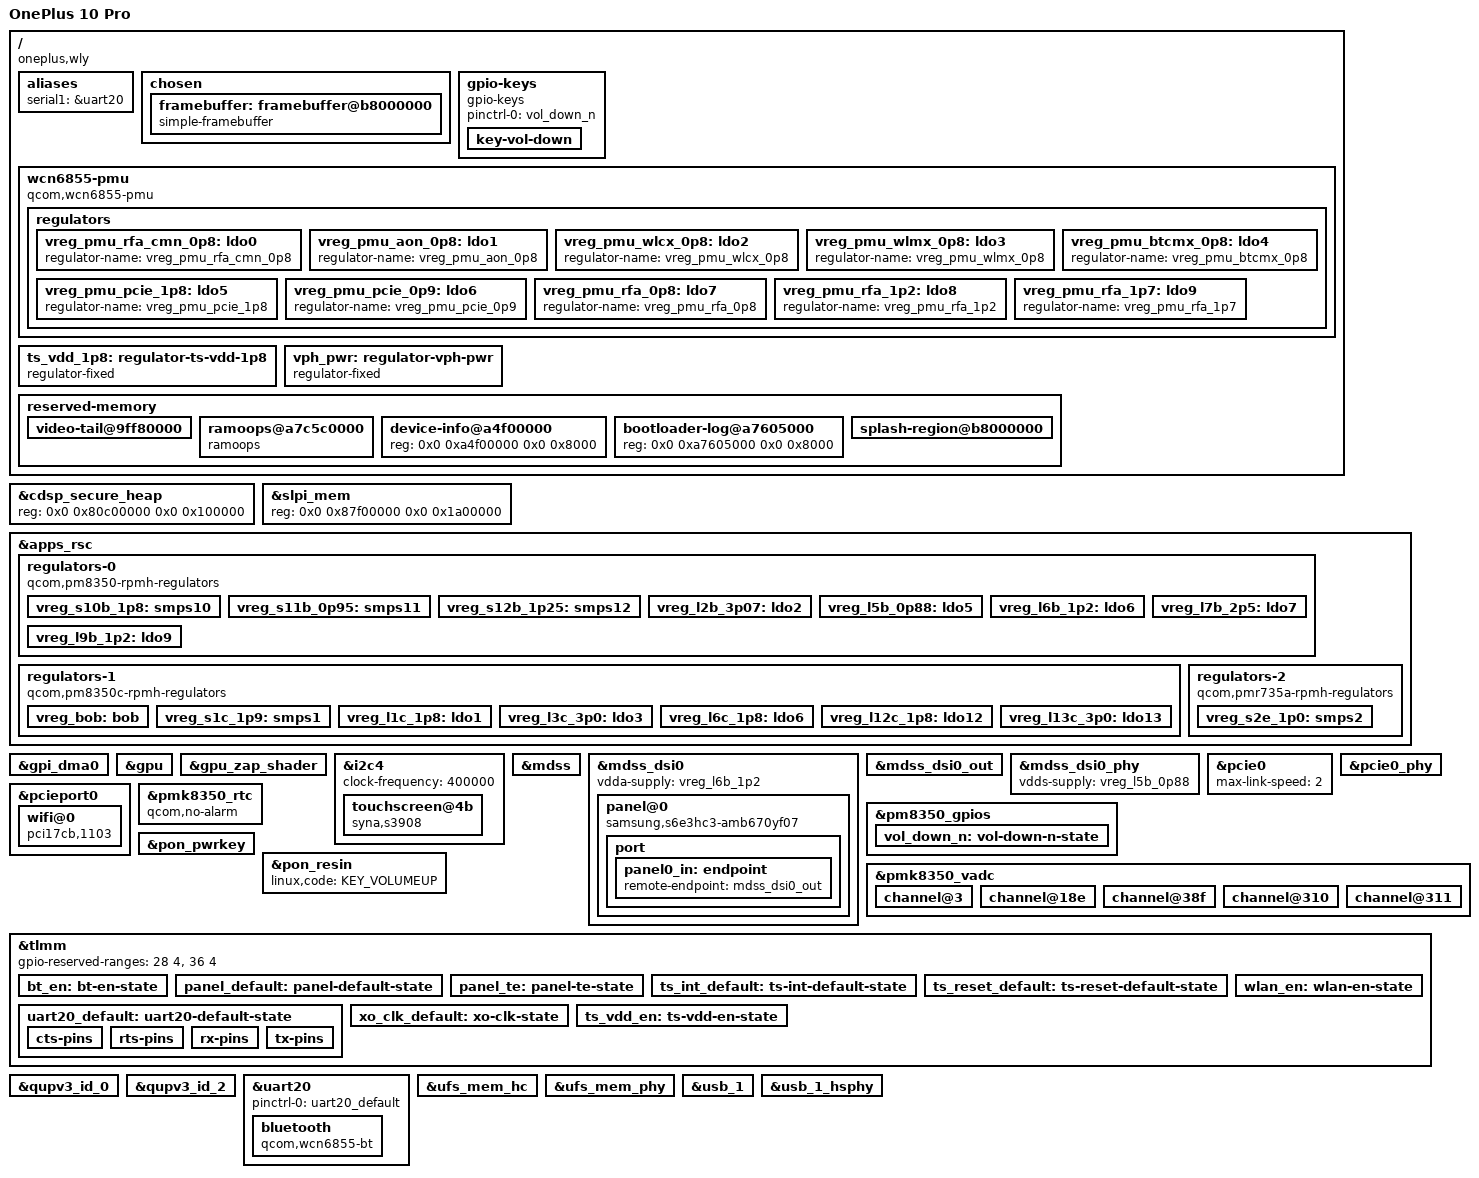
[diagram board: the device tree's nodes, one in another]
// SPDX-License-Identifier: GPL-2.0-only
/*
 * OnePlus 10 Pro (wly, NE2215): first-light device tree.
 *
 * Describes the splash framebuffer, the display (DSI panel), the GPU, touch,
 * Wi-Fi, Bluetooth, UFS, USB 2.0, the buttons and the PMK8350's RTC and
 * ADC. Every value comes from the stock device tree that ABL hands to the
 * OxygenOS 15.0.0.1302 kernel (/sys/firmware/fdt).
 */

/dts-v1/;

#include <dt-bindings/gpio/gpio.h>
#include <dt-bindings/iio/qcom,spmi-adc7-pm8350.h>
#include <dt-bindings/iio/qcom,spmi-adc7-pm8350b.h>
#include <dt-bindings/iio/qcom,spmi-adc7-pmk8350.h>
#include <dt-bindings/input/linux-event-codes.h>
#include <dt-bindings/regulator/qcom,rpmh-regulator.h>

#include "sm8450.dtsi"
#include "pm8350.dtsi"
#include "pm8350c.dtsi"
#include "pmk8350.dtsi"

/ {
	model = "OnePlus 10 Pro";
	compatible = "oneplus,wly", "qcom,sm8450";
	chassis-type = "handset";

	/* What stock carries, so ABL picks this DTB: SoC ids and the MTP board */
	qcom,msm-id = <0x1e2 0x20000>, <0x1c9 0x10000>, <0x1c9 0x20000>,
		      <0x228 0x10000>, <0x1e2 0x10000>;
	qcom,board-id = <0x10008 0>;

	aliases {
		serial1 = &uart20;
	};

	chosen {
		#address-cells = <2>;
		#size-cells = <2>;
		ranges;

		/*
		 * The panel's default timing is fhd_sdc_60 (1080x2412); the
		 * native 1440x3216 mode is only selected later by Android.
		 * ABL scans out at 1080x2412: the console reads correctly.
		 */
		framebuffer: framebuffer@b8000000 {
			compatible = "simple-framebuffer";
			reg = <0x0 0xb8000000 0x0 0x2b00000>;
			width = <1080>;
			height = <2412>;
			stride = <(1080 * 4)>;
			format = "a8r8g8b8";
		};
	};

	gpio-keys {
		compatible = "gpio-keys";

		pinctrl-0 = <&vol_down_n>;
		pinctrl-names = "default";

		/* Stock labels this "volume_up", but it reports KEY_VOLUMEDOWN */
		key-vol-down {
			label = "Volume Down";
			gpios = <&pm8350_gpios 6 GPIO_ACTIVE_LOW>;
			linux,code = <KEY_VOLUMEDOWN>;
			debounce-interval = <15>;
			linux,can-disable;
			wakeup-source;
		};
	};

	/* The QCA6490 Wi-Fi/Bluetooth chip's power sequencer, as stock wires it */
	wcn6855-pmu {
		compatible = "qcom,wcn6855-pmu";

		pinctrl-0 = <&bt_en>, <&wlan_en>, <&xo_clk_default>;
		pinctrl-names = "default";

		wlan-enable-gpios = <&tlmm 80 GPIO_ACTIVE_HIGH>;
		bt-enable-gpios = <&tlmm 81 GPIO_ACTIVE_HIGH>;
		swctrl-gpios = <&tlmm 82 GPIO_ACTIVE_HIGH>;
		xo-clk-gpios = <&tlmm 204 GPIO_ACTIVE_HIGH>;

		vddio-supply = <&vreg_s10b_1p8>;
		vddaon-supply = <&vreg_s11b_0p95>;
		vddpmu-supply = <&vreg_s12b_1p25>;
		vddpmumx-supply = <&vreg_s2e_1p0>;
		vddpmucx-supply = <&vreg_s11b_0p95>;
		vddrfa0p95-supply = <&vreg_s11b_0p95>;
		vddrfa1p3-supply = <&vreg_s12b_1p25>;
		vddrfa1p9-supply = <&vreg_s1c_1p9>;
		vddpcie1p3-supply = <&vreg_s12b_1p25>;
		vddpcie1p9-supply = <&vreg_s1c_1p9>;

		regulators {
			vreg_pmu_rfa_cmn_0p8: ldo0 {
				regulator-name = "vreg_pmu_rfa_cmn_0p8";
			};

			vreg_pmu_aon_0p8: ldo1 {
				regulator-name = "vreg_pmu_aon_0p8";
			};

			vreg_pmu_wlcx_0p8: ldo2 {
				regulator-name = "vreg_pmu_wlcx_0p8";
			};

			vreg_pmu_wlmx_0p8: ldo3 {
				regulator-name = "vreg_pmu_wlmx_0p8";
			};

			vreg_pmu_btcmx_0p8: ldo4 {
				regulator-name = "vreg_pmu_btcmx_0p8";
			};

			vreg_pmu_pcie_1p8: ldo5 {
				regulator-name = "vreg_pmu_pcie_1p8";
			};

			vreg_pmu_pcie_0p9: ldo6 {
				regulator-name = "vreg_pmu_pcie_0p9";
			};

			vreg_pmu_rfa_0p8: ldo7 {
				regulator-name = "vreg_pmu_rfa_0p8";
			};

			vreg_pmu_rfa_1p2: ldo8 {
				regulator-name = "vreg_pmu_rfa_1p2";
			};

			vreg_pmu_rfa_1p7: ldo9 {
				regulator-name = "vreg_pmu_rfa_1p7";
			};
		};
	};

	/* The touchscreen's 1.8 V rail, switched by GPIO 186 (stock: enable1v8_gpio) */
	ts_vdd_1p8: regulator-ts-vdd-1p8 {
		compatible = "regulator-fixed";
		regulator-name = "ts_vdd_1p8";
		regulator-min-microvolt = <1800000>;
		regulator-max-microvolt = <1800000>;
		vin-supply = <&vreg_l6c_1p8>;
		gpio = <&tlmm 186 GPIO_ACTIVE_HIGH>;
		enable-active-high;
		pinctrl-0 = <&ts_vdd_en>;
		pinctrl-names = "default";
	};

	vph_pwr: regulator-vph-pwr {
		compatible = "regulator-fixed";
		regulator-name = "vph_pwr";
		regulator-min-microvolt = <3700000>;
		regulator-max-microvolt = <3700000>;
		regulator-always-on;
		regulator-boot-on;
	};

	reserved-memory {
		/*
		 * Stock places the video firmware at 0x9fd00000 (0x700000), over
		 * what sm8450.dtsi gives rmtfs; stock allocates rmtfs from a pool.
		 * Keep the tail past rmtfs out of the kernel's hands until venus
		 * and rmtfs are brought up and the layout is moved to match stock.
		 */
		video-tail@9ff80000 {
			reg = <0x0 0x9ff80000 0x0 0x480000>;
			no-map;
		};

		/*
		 * Where stock's dynamically placed ramoops lands (dmesg: "ramoops:
		 * using 0x240000@0xa7c5c0000"), so a stock or rooted RAM boot after
		 * a warm reset can read this kernel's last log from pstore.
		 */
		ramoops@a7c5c0000 {
			compatible = "ramoops";
			reg = <0xa 0x7c5c0000 0x0 0x240000>;
			console-size = <0x40000>;
			pmsg-size = <0x200000>;
			mem-type = <2>;
			no-map;
		};

		/* OnePlus' device info and bootloader log, written before Linux */
		device-info@a4f00000 {
			reg = <0x0 0xa4f00000 0x0 0x8000>;
		};

		bootloader-log@a7605000 {
			reg = <0x0 0xa7605000 0x0 0x8000>;
		};

		/*
		 * The bootloader will only keep display hardware enabled
		 * if this memory region is named exactly 'splash_region'
		 */
		splash-region@b8000000 {
			reg = <0x0 0xb8000000 0x0 0x2b00000>;
			no-map;
		};
	};
};

/* Stock's SLPI region starts 1 MiB below sm8450.dtsi's and ends at the same place */
/*
 * Stock gives the CDSP secure heap 1 MiB, not sm8450.dtsi's 70; the rest is
 * plain RAM on this board, where the 70 MiB failed to reserve ("failed to
 * reserve memory for node 'memory@80c00000'") once the kexec'd kernel sat
 * in it.
 */
&cdsp_secure_heap {
	reg = <0x0 0x80c00000 0x0 0x100000>;
};

&slpi_mem {
	reg = <0x0 0x87f00000 0x0 0x1a00000>;
};

&apps_rsc {
	regulators-0 {
		compatible = "qcom,pm8350-rpmh-regulators";
		qcom,pmic-id = "b";

		vdd-s1-supply = <&vph_pwr>;
		vdd-s2-supply = <&vph_pwr>;
		vdd-s3-supply = <&vph_pwr>;
		vdd-s4-supply = <&vph_pwr>;
		vdd-s5-supply = <&vph_pwr>;
		vdd-s6-supply = <&vph_pwr>;
		vdd-s7-supply = <&vph_pwr>;
		vdd-s8-supply = <&vph_pwr>;
		vdd-s9-supply = <&vph_pwr>;
		vdd-s10-supply = <&vph_pwr>;
		vdd-s11-supply = <&vph_pwr>;
		vdd-s12-supply = <&vph_pwr>;

		vdd-l2-l7-supply = <&vreg_bob>;
		vdd-l3-l5-supply = <&vreg_bob>;

		vreg_s10b_1p8: smps10 {
			regulator-min-microvolt = <1800000>;
			regulator-max-microvolt = <1800000>;
		};

		vreg_s11b_0p95: smps11 {
			regulator-min-microvolt = <966000>;
			regulator-max-microvolt = <1104000>;
		};

		vreg_s12b_1p25: smps12 {
			regulator-min-microvolt = <1350000>;
			regulator-max-microvolt = <1400000>;
		};

		vreg_l2b_3p07: ldo2 {
			regulator-min-microvolt = <3072000>;
			regulator-max-microvolt = <3072000>;
			regulator-initial-mode = <RPMH_REGULATOR_MODE_HPM>;
		};

		vreg_l5b_0p88: ldo5 {
			regulator-min-microvolt = <880000>;
			regulator-max-microvolt = <912000>;
			regulator-initial-mode = <RPMH_REGULATOR_MODE_HPM>;
		};

		vreg_l6b_1p2: ldo6 {
			regulator-min-microvolt = <1200000>;
			regulator-max-microvolt = <1200000>;
			regulator-initial-mode = <RPMH_REGULATOR_MODE_HPM>;
		};

		vreg_l7b_2p5: ldo7 {
			regulator-min-microvolt = <2504000>;
			regulator-max-microvolt = <2504000>;
			regulator-initial-mode = <RPMH_REGULATOR_MODE_HPM>;
		};

		vreg_l9b_1p2: ldo9 {
			regulator-min-microvolt = <1200000>;
			regulator-max-microvolt = <1200000>;
			regulator-initial-mode = <RPMH_REGULATOR_MODE_HPM>;
		};
	};

	regulators-1 {
		compatible = "qcom,pm8350c-rpmh-regulators";
		qcom,pmic-id = "c";

		vdd-s1-supply = <&vph_pwr>;
		vdd-s2-supply = <&vph_pwr>;
		vdd-s3-supply = <&vph_pwr>;
		vdd-s4-supply = <&vph_pwr>;
		vdd-s5-supply = <&vph_pwr>;
		vdd-s6-supply = <&vph_pwr>;
		vdd-s7-supply = <&vph_pwr>;
		vdd-s8-supply = <&vph_pwr>;
		vdd-s9-supply = <&vph_pwr>;
		vdd-s10-supply = <&vph_pwr>;

		vdd-l1-l12-supply = <&vreg_bob>;
		vdd-l2-l8-supply = <&vreg_bob>;
		vdd-l3-l4-l5-l7-l13-supply = <&vreg_bob>;
		vdd-l6-l9-l11-supply = <&vreg_bob>;

		vdd-bob-supply = <&vph_pwr>;

		vreg_bob: bob {
			regulator-min-microvolt = <3008000>;
			regulator-max-microvolt = <3960000>;
			regulator-initial-mode = <RPMH_REGULATOR_MODE_AUTO>;
		};

		/* stock: qcom,vdd-wlan-rfa1-config, 1.9 to 2.1 V */
		vreg_s1c_1p9: smps1 {
			regulator-min-microvolt = <1900000>;
			regulator-max-microvolt = <2100000>;
		};

		vreg_l1c_1p8: ldo1 {
			regulator-min-microvolt = <1800000>;
			regulator-max-microvolt = <1800000>;
			regulator-initial-mode = <RPMH_REGULATOR_MODE_HPM>;
		};

		vreg_l3c_3p0: ldo3 {
			regulator-min-microvolt = <3008000>;
			regulator-max-microvolt = <3008000>;
			regulator-initial-mode = <RPMH_REGULATOR_MODE_HPM>;
		};

		vreg_l6c_1p8: ldo6 {
			regulator-min-microvolt = <1800000>;
			regulator-max-microvolt = <1800000>;
			regulator-initial-mode = <RPMH_REGULATOR_MODE_HPM>;
		};

		vreg_l12c_1p8: ldo12 {
			regulator-min-microvolt = <1800000>;
			regulator-max-microvolt = <1800000>;
			regulator-initial-mode = <RPMH_REGULATOR_MODE_HPM>;
		};

		vreg_l13c_3p0: ldo13 {
			regulator-min-microvolt = <3000000>;
			regulator-max-microvolt = <3000000>;
			regulator-initial-mode = <RPMH_REGULATOR_MODE_HPM>;
		};
	};

	regulators-2 {
		compatible = "qcom,pmr735a-rpmh-regulators";
		qcom,pmic-id = "e";

		vdd-s1-supply = <&vph_pwr>;
		vdd-s2-supply = <&vph_pwr>;
		vdd-s3-supply = <&vph_pwr>;

		/* stock: qcom,vdd-wlan-aon-config, 1.012 V */
		vreg_s2e_1p0: smps2 {
			regulator-min-microvolt = <1012000>;
			regulator-max-microvolt = <1012000>;
		};
	};
};

&gpi_dma0 {
	status = "okay";
};

&gpu {
	status = "okay";
};

&gpu_zap_shader {
	firmware-name = "qcom/sm8450/oneplus/wly/a730_zap.mbn";
};

&i2c4 {
	clock-frequency = <400000>;
	status = "okay";

	touchscreen@4b {
		compatible = "syna,s3908";
		reg = <0x4b>;

		interrupts-extended = <&tlmm 21 IRQ_TYPE_LEVEL_LOW>;
		reset-gpios = <&tlmm 20 GPIO_ACTIVE_LOW>;

		vdd-supply = <&ts_vdd_1p8>;
		avdd-supply = <&vreg_l3c_3p0>;

		pinctrl-0 = <&ts_int_default>, <&ts_reset_default>;
		pinctrl-names = "default";

		touchscreen-x-mm = <70>;
		touchscreen-y-mm = <156>;
	};
};

&mdss {
	status = "okay";
};

&mdss_dsi0 {
	vdda-supply = <&vreg_l6b_1p2>;
	status = "okay";

	panel@0 {
		compatible = "samsung,s6e3hc3-amb670yf07";
		reg = <0>;

		vddio-supply = <&vreg_l12c_1p8>;
		vci-supply = <&vreg_l13c_3p0>;
		reset-gpios = <&tlmm 3 GPIO_ACTIVE_LOW>;
		enable-gpios = <&tlmm 90 GPIO_ACTIVE_HIGH>;

		pinctrl-0 = <&panel_default>, <&panel_te>;
		pinctrl-names = "default";

		port {
			panel0_in: endpoint {
				remote-endpoint = <&mdss_dsi0_out>;
			};
		};
	};
};

&mdss_dsi0_out {
	remote-endpoint = <&panel0_in>;
	data-lanes = <0 1 2 3>;
};

&mdss_dsi0_phy {
	vdds-supply = <&vreg_l5b_0p88>;
	status = "okay";
};

&pcie0 {
	/*
	 * The QCA6490's MSIs never reach the GIC ITS: the root port's own
	 * MSIs do, and the chip programs a valid doorbell address, but the
	 * WLAN firmware's boot handshake times out waiting for its BHI
	 * interrupt. The controller's internal MSI controller works.
	 */
	/delete-property/ msi-map;
	/delete-property/ msi-map-mask;

	max-link-speed = <2>;
	status = "okay";
};

&pcie0_phy {
	vdda-phy-supply = <&vreg_l5b_0p88>;
	vdda-pll-supply = <&vreg_l6b_1p2>;
	status = "okay";
};

&pcieport0 {
	wifi@0 {
		compatible = "pci17cb,1103";
		reg = <0x10000 0x0 0x0 0x0 0x0>;

		vddrfacmn-supply = <&vreg_pmu_rfa_cmn_0p8>;
		vddaon-supply = <&vreg_pmu_aon_0p8>;
		vddwlcx-supply = <&vreg_pmu_wlcx_0p8>;
		vddwlmx-supply = <&vreg_pmu_wlmx_0p8>;
		vddpcie1p8-supply = <&vreg_pmu_pcie_1p8>;
		vddpcie0p9-supply = <&vreg_pmu_pcie_0p9>;
		vddrfa0p8-supply = <&vreg_pmu_rfa_0p8>;
		vddrfa1p2-supply = <&vreg_pmu_rfa_1p2>;
		vddrfa1p8-supply = <&vreg_pmu_rfa_1p7>;
	};
};

&pm8350_gpios {
	vol_down_n: vol-down-n-state {
		pins = "gpio6";
		function = "normal";
		power-source = <1>;
		bias-pull-up;
		input-enable;
	};
};

/*
 * Read-only for now: no allow-set-time (the secure world owns setting it)
 * and no alarm, which stock's Android may own. Without a stored offset the
 * time is the counter since the PMIC's last reset, not the wall clock.
 */
&pmk8350_rtc {
	qcom,no-alarm;
	status = "okay";
};

/*
 * Stock's power channels on the PMK8350's ADC: the main rail and the
 * battery (two cells in series). The PM8350B's are read here by channel
 * number (SID 3); the PMIC itself is not described yet. Stock also reads
 * the charger's temperature (0x310) and the USB input (0x311), which the
 * adc5 driver's ADC7 table has no scaling for yet.
 */
&pmk8350_vadc {
	status = "okay";

	channel@3 {
		reg = <PMK8350_ADC7_DIE_TEMP>;
		label = "pmk8350_die_temp";
	};

	channel@18e {
		reg = <PM8350_ADC7_VPH_PWR(1)>;
		label = "pm8350_vph_pwr";
	};

	channel@38f {
		reg = <PM8350B_ADC7_VBAT_SNS>;
		label = "pm8350b_vbat_sns";
		qcom,pre-scaling = <1 3>;
	};

	channel@310 {
		reg = <PM8350B_ADC7_CHG_TEMP>;
		label = "pm8350b_chg_temp";
	};

	channel@311 {
		reg = <PM8350B_ADC7_USB_IN_V_16>;
		label = "pm8350b_usb_in_v_div_16";
	};
};

&pon_pwrkey {
	status = "okay";
};

&pon_resin {
	linux,code = <KEY_VOLUMEUP>;
	status = "okay";
};

&tlmm {
	/* Owned by the secure world on stock (qcom,gpios-reserved) */
	gpio-reserved-ranges = <28 4>, <36 4>;

	bt_en: bt-en-state {
		pins = "gpio81";
		function = "gpio";
		drive-strength = <16>;
		output-low;
		bias-pull-down;
	};

	panel_default: panel-default-state {
		pins = "gpio3", "gpio90";
		function = "gpio";
		drive-strength = <8>;
		bias-disable;
	};

	panel_te: panel-te-state {
		pins = "gpio86";
		function = "mdp_vsync";
		drive-strength = <2>;
		bias-pull-down;
	};

	ts_int_default: ts-int-default-state {
		pins = "gpio21";
		function = "gpio";
		drive-strength = <8>;
		bias-disable;
	};

	ts_reset_default: ts-reset-default-state {
		pins = "gpio20";
		function = "gpio";
		drive-strength = <8>;
		bias-disable;
	};

	uart20_default: uart20-default-state {
		cts-pins {
			pins = "gpio76";
			function = "qup20";
			bias-disable;
		};

		rts-pins {
			pins = "gpio77";
			function = "qup20";
			bias-disable;
		};

		rx-pins {
			pins = "gpio78";
			function = "qup20";
			bias-disable;
		};

		tx-pins {
			pins = "gpio79";
			function = "qup20";
			bias-disable;
		};
	};

	wlan_en: wlan-en-state {
		pins = "gpio80";
		function = "gpio";
		drive-strength = <16>;
		output-low;
		bias-pull-down;
	};

	xo_clk_default: xo-clk-state {
		pins = "gpio204";
		function = "gpio";
		drive-strength = <16>;
		output-low;
		bias-pull-down;
	};

	ts_vdd_en: ts-vdd-en-state {
		pins = "gpio186";
		function = "gpio";
		drive-strength = <2>;
		bias-disable;
	};
};

&qupv3_id_0 {
	status = "okay";
};

&qupv3_id_2 {
	status = "okay";
};

&uart20 {
	pinctrl-0 = <&uart20_default>;
	pinctrl-names = "default";

	status = "okay";

	bluetooth {
		compatible = "qcom,wcn6855-bt";

		vddrfacmn-supply = <&vreg_pmu_rfa_cmn_0p8>;
		vddaon-supply = <&vreg_pmu_aon_0p8>;
		vddwlcx-supply = <&vreg_pmu_wlcx_0p8>;
		vddwlmx-supply = <&vreg_pmu_wlmx_0p8>;
		vddbtcmx-supply = <&vreg_pmu_btcmx_0p8>;
		vddrfa0p8-supply = <&vreg_pmu_rfa_0p8>;
		vddrfa1p2-supply = <&vreg_pmu_rfa_1p2>;
		vddrfa1p7-supply = <&vreg_pmu_rfa_1p7>;
	};
};

&ufs_mem_hc {
	reset-gpios = <&tlmm 210 GPIO_ACTIVE_LOW>;

	vcc-supply = <&vreg_l7b_2p5>;
	vcc-max-microamp = <1100000>;
	vccq-supply = <&vreg_l9b_1p2>;
	vccq-max-microamp = <1200000>;
	vdd-hba-supply = <&vreg_l9b_1p2>;

	status = "okay";
};

&ufs_mem_phy {
	vdda-phy-supply = <&vreg_l5b_0p88>;
	vdda-pll-supply = <&vreg_l6b_1p2>;

	status = "okay";
};

&usb_1 {
	/* Keep USB 2.0 only for now */
	qcom,select-utmi-as-pipe-clk;

	dr_mode = "peripheral";
	maximum-speed = "high-speed";
	/* Remove USB3 phy */
	phys = <&usb_1_hsphy>;
	phy-names = "usb2-phy";

	status = "okay";
};

&usb_1_hsphy {
	vdda-pll-supply = <&vreg_l5b_0p88>;
	vdda18-supply = <&vreg_l1c_1p8>;
	vdda33-supply = <&vreg_l2b_3p07>;

	status = "okay";
};
